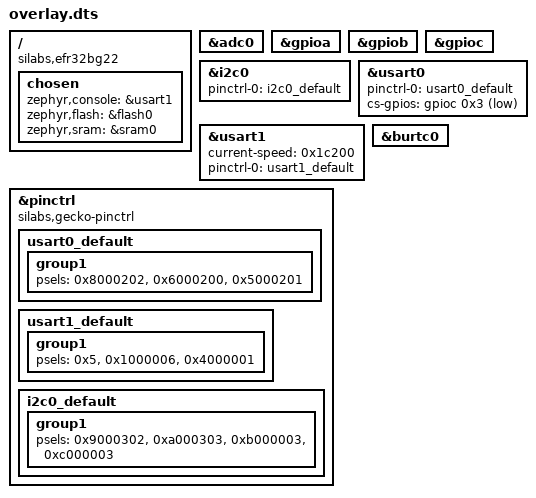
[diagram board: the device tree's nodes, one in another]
/ {
	compatible = "silabs,efr32bg22", "silabs,efr32bg22c224f512im40", "silabs,efr32bg_brd4184a";
	chosen {
		zephyr,console = &usart1;
		zephyr,flash = &flash0;
		zephyr,sram = &sram0;
	};
};
&adc0{
	status = "okay";
};
&gpioa{
	status = "okay";
};
&gpiob{
	status = "okay";
};
&gpioc{
	status = "okay";
};
&i2c0{
	status = "okay";
	pinctrl-0 = < &i2c0_default >;
	pinctrl-names = "default";
};
&usart0{
	status = "okay";
	pinctrl-0 = < &usart0_default >;
	pinctrl-names = "default";
	cs-gpios = < &gpioc 0x3 0x1 >;
};
&usart1{
	status = "okay";
	current-speed = < 0x1c200 >;
	pinctrl-0 = < &usart1_default >;
	pinctrl-names = "default";
};
&burtc0{
	status = "okay";
};
&pinctrl{
	compatible = "silabs,gecko-pinctrl";
	usart0_default: usart0_default {
		group1 {
			psels = < 0x8000202 >, < 0x6000200 >, < 0x5000201 >;
		};
	};
	usart1_default: usart1_default {
		group1 {
			psels = < 0x5 >, < 0x1000006 >, < 0x4000001 >;
		};
	};
	i2c0_default: i2c0_default {
		group1 {
			psels = < 0x9000302 >, < 0xa000303 >, < 0xb000003 >, < 0xc000003 >;
		};
	};
};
